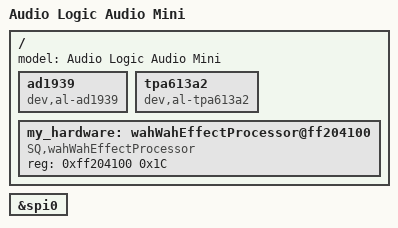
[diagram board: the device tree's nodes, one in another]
// SPDX-License-Identifier: GPL-2.0+
#include "socfpga_cyclone5_de0.dtsi"

/{
    model = "Audio Logic Audio Mini";

    ad1939 {
        compatible = "dev,al-ad1939";
    };

    tpa613a2 {
        compatible = "dev,al-tpa613a2";
    };

    my_hardware: wahWahEffectProcessor@ff204100 {
    	compatible = "SQ,wahWahEffectProcessor";
    	reg = <0xff204100 0x1C>;
    };
};

&spi0{
    status = "okay";
};
